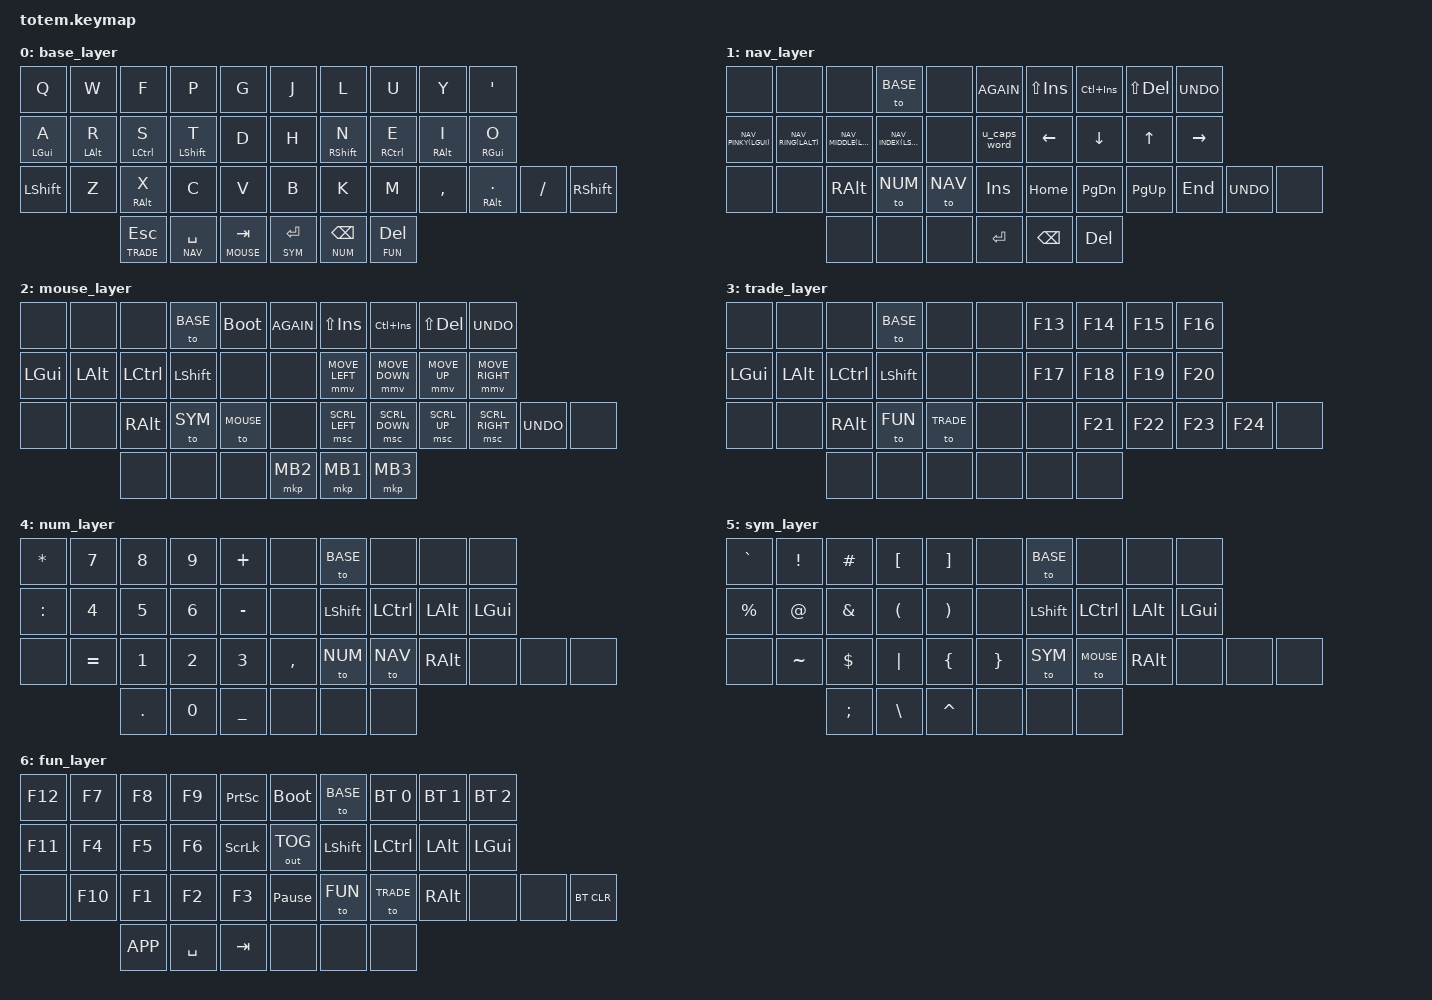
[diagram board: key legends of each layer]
#include <behaviors.dtsi>
#include <dt-bindings/zmk/keys.h>
#include <dt-bindings/zmk/modifiers.h>
#include <dt-bindings/zmk/mouse.h>
#include <dt-bindings/zmk/bt.h>
#include <dt-bindings/zmk/outputs.h>
#define ZMK_POINTING_DEFAULT_MOVE_VAL 1800
#include <dt-bindings/zmk/pointing.h>

#define BASE 0
#define NAV 1
#define MOUSE 2
#define TRADE 3
#define NUM 4
#define SYM 5
#define FUN 6
#define NAV_PINKY(mod) &nav_home_pinky mod MACRO_PLACEHOLDER
#define NAV_RING(mod) &nav_home_ring mod MACRO_PLACEHOLDER
#define NAV_MIDDLE(mod) &nav_home_middle mod MACRO_PLACEHOLDER
#define NAV_INDEX(mod) &nav_home_index mod MACRO_PLACEHOLDER

&mmv {
    time-to-max-speed-ms = <600>;
    acceleration-exponent = <2>;
};

/ {
    behaviors {
        hml: homerow_mods_left {
            compatible = "zmk,behavior-hold-tap";
            #binding-cells = <2>;
            /*
             * Home-row mods tuned so a held key reliably becomes a modifier
             * instead of repeating the letter (the "aaaa" misfire):
             *   - flavor "balanced": triggers the hold as soon as another key
             *     is pressed AND released while held, so fast chords still
             *     register as mods (was "tap-preferred", which required
             *     holding past the full tapping term first).
             *   - require-prior-idle-ms 300 -> 120: previously any keypress
             *     within 300ms forced a tap regardless of hold duration, so
             *     reaching for a mod right after typing repeated the letter.
             *   - tapping-term-ms 280 -> 200: quicker hold decision.
             */
            tapping-term-ms = <200>;
            quick-tap-ms = <175>;
            require-prior-idle-ms = <120>;
            flavor = "balanced";
            hold-trigger-key-positions = <5 6 7 8 9 15 16 17 18 19 26 27 28 29 30 31 35 36 37>;
            hold-trigger-on-release;
            bindings = <&kp>, <&kp>;
        };

        hmr: homerow_mods_right {
            compatible = "zmk,behavior-hold-tap";
            #binding-cells = <2>;
            /* See hml above for the rationale behind these values. */
            tapping-term-ms = <200>;
            quick-tap-ms = <175>;
            require-prior-idle-ms = <120>;
            flavor = "balanced";
            hold-trigger-key-positions = <0 1 2 3 4 10 11 12 13 14 20 21 22 23 24 25 32 33 34>;
            hold-trigger-on-release;
            bindings = <&kp>, <&kp>;
        };

        u_lt: u_lt {
            compatible = "zmk,behavior-hold-tap";
            #binding-cells = <2>;
            tapping-term-ms = <200>;
            flavor = "tap-preferred";
            bindings = <&mo>, <&kp>;
        };

        u_caps_word: u_caps_word {
            compatible = "zmk,behavior-mod-morph";
            #binding-cells = <0>;
            bindings = <&caps_word>, <&kp CAPS>;
            mods = <(MOD_LSFT|MOD_RSFT)>;
        };

        nav_home_pinky_tap: nav_home_pinky_tap {
            compatible = "zmk,behavior-macro-one-param";
            #binding-cells = <1>;
            bindings
                = <&kp LC(N1)>
                , <&kp LC(N5)>
                ;
        };

        nav_home_ring_tap: nav_home_ring_tap {
            compatible = "zmk,behavior-macro-one-param";
            #binding-cells = <1>;
            bindings
                = <&kp LC(N2)>
                , <&kp LC(N6)>
                ;
        };

        nav_home_middle_tap: nav_home_middle_tap {
            compatible = "zmk,behavior-macro-one-param";
            #binding-cells = <1>;
            bindings
                = <&kp LC(N3)>
                , <&kp LC(N7)>
                ;
        };

        nav_home_index_tap: nav_home_index_tap {
            compatible = "zmk,behavior-macro-one-param";
            #binding-cells = <1>;
            bindings
                = <&kp LC(N4)>
                , <&kp LC(N8)>
                ;
        };

        nav_home_pinky: nav_home_pinky {
            compatible = "zmk,behavior-hold-tap";
            #binding-cells = <2>;
            tapping-term-ms = <200>;
            flavor = "tap-preferred";
            bindings = <&kp>, <&nav_home_pinky_tap>;
        };

        nav_home_ring: nav_home_ring {
            compatible = "zmk,behavior-hold-tap";
            #binding-cells = <2>;
            tapping-term-ms = <200>;
            flavor = "tap-preferred";
            bindings = <&kp>, <&nav_home_ring_tap>;
        };

        nav_home_middle: nav_home_middle {
            compatible = "zmk,behavior-hold-tap";
            #binding-cells = <2>;
            tapping-term-ms = <200>;
            flavor = "tap-preferred";
            bindings = <&kp>, <&nav_home_middle_tap>;
        };

        nav_home_index: nav_home_index {
            compatible = "zmk,behavior-hold-tap";
            #binding-cells = <2>;
            tapping-term-ms = <200>;
            flavor = "tap-preferred";
            bindings = <&kp>, <&nav_home_index_tap>;
        };
    };

    keymap {
        compatible = "zmk,keymap";

        base_layer {
            bindings = <
                &kp Q              &kp W              &kp F              &kp P              &kp G              &kp J              &kp L              &kp U              &kp Y              &kp SQT
                &hml LGUI A        &hml LALT R        &hml LCTRL S       &hml LSHFT T       &kp D              &kp H              &hmr RSHFT N       &hmr RCTRL E       &hmr RALT I        &hmr RGUI O
                &kp LSHFT          &kp Z              &hml RALT X        &kp C              &kp V              &kp B              &kp K              &kp M              &kp COMMA          &hmr RALT DOT      &kp SLASH          &kp RSHFT
                                                       &u_lt TRADE ESC    &u_lt NAV SPACE    &u_lt MOUSE TAB    &u_lt SYM RET      &u_lt NUM BSPC     &u_lt FUN DEL
            >;
        };

        nav_layer {
            bindings = <
                &none              &none              &none              &to BASE           &none              &kp K_AGAIN        &kp LS(INS)        &kp LC(INS)        &kp LS(DEL)        &kp UNDO
                NAV_PINKY(LGUI)    NAV_RING(LALT)     NAV_MIDDLE(LCTRL)  NAV_INDEX(LSHFT)   &none              &u_caps_word       &kp LEFT           &kp DOWN           &kp UP             &kp RIGHT
                &none              &none              &kp RALT           &to NUM            &to NAV            &kp INS            &kp HOME           &kp PG_DN          &kp PG_UP          &kp END            &kp UNDO           &none
                                                       &none              &none              &none              &kp RET            &kp BSPC           &kp DEL
            >;
        };

        mouse_layer {
            bindings = <
                &none              &none              &none              &to BASE           &bootloader        &kp K_AGAIN        &kp LS(INS)        &kp LC(INS)        &kp LS(DEL)        &kp UNDO
                &kp LGUI           &kp LALT           &kp LCTRL          &kp LSHFT          &none              &none              &mmv MOVE_LEFT     &mmv MOVE_DOWN     &mmv MOVE_UP       &mmv MOVE_RIGHT
                &none              &none              &kp RALT           &to SYM            &to MOUSE          &none              &msc SCRL_LEFT     &msc SCRL_DOWN     &msc SCRL_UP       &msc SCRL_RIGHT    &kp UNDO           &none
                                                       &none              &none              &none              &mkp MB2           &mkp MB1           &mkp MB3
            >;
        };

        trade_layer {
            bindings = <
                &none              &none              &none              &to BASE           &none              &none              &kp F13            &kp F14            &kp F15            &kp F16
                &kp LGUI           &kp LALT           &kp LCTRL          &kp LSHFT          &none              &none              &kp F17            &kp F18            &kp F19            &kp F20
                &none              &none              &kp RALT           &to FUN            &to TRADE          &none              &none              &kp F21            &kp F22            &kp F23            &kp F24            &none
                                                       &none              &none              &none              &none              &none              &none
            >;
        };

        num_layer {
            bindings = <
                &kp ASTRK          &kp N7             &kp N8             &kp N9             &kp PLUS           &none              &to BASE           &none              &none              &none
                &kp COLON          &kp N4             &kp N5             &kp N6             &kp MINUS          &none              &kp LSHFT          &kp LCTRL          &kp LALT           &kp LGUI
                &none              &kp EQUAL          &kp N1             &kp N2             &kp N3             &kp COMMA          &to NUM            &to NAV            &kp RALT           &none              &none              &none
                                                       &kp DOT            &kp N0             &kp UNDER          &none              &none              &none
            >;
        };

        sym_layer {
            bindings = <
                &kp GRAVE          &kp EXCL           &kp HASH           &kp LBKT           &kp RBKT           &none              &to BASE           &none              &none              &none
                &kp PRCNT          &kp AT             &kp AMPS           &kp LPAR           &kp RPAR           &none              &kp LSHFT          &kp LCTRL          &kp LALT           &kp LGUI
                &none              &kp TILDE          &kp DLLR           &kp PIPE           &kp LBRC           &kp RBRC           &to SYM            &to MOUSE          &kp RALT           &none              &none              &none
                                                       &kp SEMI           &kp BSLH           &kp CARET          &none              &none              &none
            >;
        };

        fun_layer {
            bindings = <
                &kp F12            &kp F7             &kp F8             &kp F9             &kp PSCRN          &bootloader        &to BASE           &bt BT_SEL 0       &bt BT_SEL 1       &bt BT_SEL 2
                &kp F11            &kp F4             &kp F5             &kp F6             &kp SLCK           &out OUT_TOG       &kp LSHFT          &kp LCTRL          &kp LALT           &kp LGUI
                &none              &kp F10            &kp F1             &kp F2             &kp F3             &kp PAUSE_BREAK    &to FUN            &to TRADE          &kp RALT           &none              &none              &bt BT_CLR
                                                       &kp K_APP          &kp SPACE          &kp TAB            &none              &none              &none
            >;
        };
    };
};
